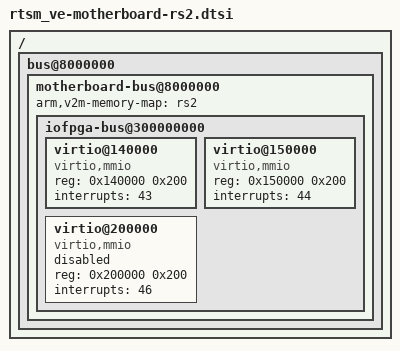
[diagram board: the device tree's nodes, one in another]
// SPDX-License-Identifier: GPL-2.0
/*
 * ARM Ltd. Fast Models
 *
 * "rs2" extension for the v2m motherboard
 */
/ {
	bus@8000000 {
		motherboard-bus@8000000 {
			arm,v2m-memory-map = "rs2";

			iofpga-bus@300000000 {
				virtio@140000 {
					compatible = "virtio,mmio";
					reg = <0x140000 0x200>;
					interrupts = <43>;
				};

				virtio@150000 {
					compatible = "virtio,mmio";
					reg = <0x150000 0x200>;
					interrupts = <44>;
				};

				virtio@200000 {
					compatible = "virtio,mmio";
					reg = <0x200000 0x200>;
					interrupts = <46>;
					status = "disabled";
				};
			};
		};
	};
};
